VERSION "blueprint-1"

NS_ :

BS_:

BU_: ClimateECU BMS EngineECU BodyECU HeadUnit

CM_ "Signal database for the DriveCore HMI vertical platform lab. Single source of truth for CAN bit definitions.";

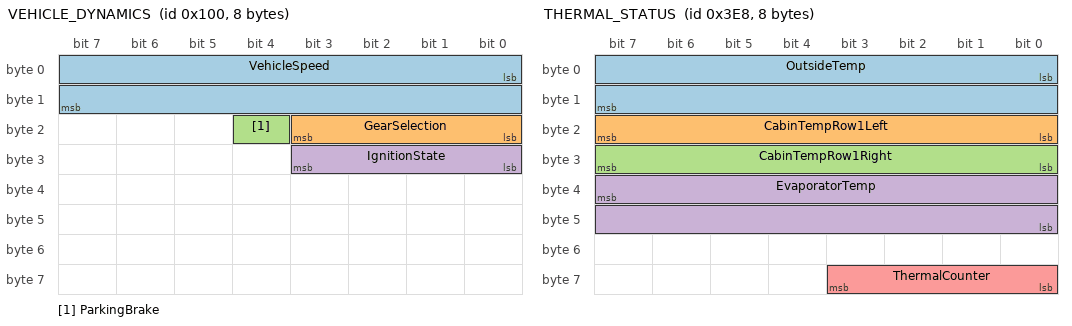
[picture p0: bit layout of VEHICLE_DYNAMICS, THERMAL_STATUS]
BO_ 256 VEHICLE_DYNAMICS: 8 EngineECU
 SG_ VehicleSpeed : 0|16@1+ (0.01,0) [0|250] "km/h" HeadUnit
 SG_ GearSelection : 16|4@1+ (1,0) [0|15] "" HeadUnit
 SG_ ParkingBrake : 20|1@1+ (1,0) [0|1] "" HeadUnit
 SG_ IgnitionState : 24|4@1+ (1,0) [0|15] "" HeadUnit

BO_ 512 BODY_STATUS: 8 BodyECU
 SG_ DoorPos : 0|8@1+ (1,0) [0|255] "" HeadUnit
 SG_ TurnSignal : 8|4@1+ (1,0) [0|15] "" HeadUnit

BO_ 768 HVAC_STATUS: 8 ClimateECU
 SG_ HvacTempSet : 0|8@1+ (0.5,10) [16|30] "degC" HeadUnit

BO_ 1000 THERMAL_STATUS: 8 ClimateECU
 SG_ OutsideTemp : 0|16@1+ (0.1,-40) [-40|125] "degC" HeadUnit
 SG_ CabinTempRow1Left : 16|8@1+ (0.5,-10) [-10|117.5] "degC" HeadUnit
 SG_ CabinTempRow1Right : 24|8@1+ (0.5,-10) [-10|117.5] "degC" HeadUnit
 SG_ EvaporatorTemp : 39|16@0- (0.01,0) [-50|150] "degC" HeadUnit
 SG_ ThermalCounter : 56|4@1+ (1,0) [0|15] "" HeadUnit

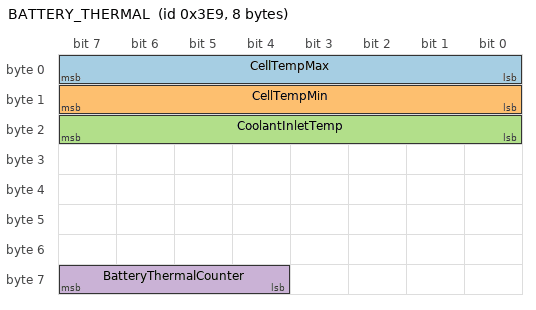
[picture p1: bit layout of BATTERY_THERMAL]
BO_ 1001 BATTERY_THERMAL: 8 BMS
 SG_ CellTempMax : 0|8@1+ (1,-40) [-40|125] "degC" HeadUnit
 SG_ CellTempMin : 8|8@1+ (1,-40) [-40|125] "degC" HeadUnit
 SG_ CoolantInletTemp : 16|8@1+ (1,-40) [-40|125] "degC" HeadUnit
 SG_ BatteryThermalCounter : 60|4@1+ (1,0) [0|15] "" HeadUnit

BA_DEF_ SG_ "VhalProperty" STRING ;
BA_DEF_ SG_ "VhalAreaId" INT 0 2147483647;
BA_DEF_ SG_ "VhalChangeMode" ENUM "ON_CHANGE","CONTINUOUS";
BA_DEF_ SG_ "VhalMinSampleRate" FLOAT 0 1000;
BA_DEF_ SG_ "VhalMaxSampleRate" FLOAT 0 1000;
BA_DEF_DEF_ "VhalProperty" "";
BA_DEF_DEF_ "VhalAreaId" 0;
BA_DEF_DEF_ "VhalChangeMode" "ON_CHANGE";
BA_DEF_DEF_ "VhalMinSampleRate" 1;
BA_DEF_DEF_ "VhalMaxSampleRate" 10;

BA_ "VhalProperty" SG_ 256 VehicleSpeed "PERF_VEHICLE_SPEED";
BA_ "VhalChangeMode" SG_ 256 VehicleSpeed "CONTINUOUS";

BA_ "VhalProperty" SG_ 256 GearSelection "GEAR_SELECTION";
BA_ "VhalProperty" SG_ 256 ParkingBrake "PARKING_BRAKE_ON";
BA_ "VhalProperty" SG_ 256 IgnitionState "IGNITION_STATE";

BA_ "VhalProperty" SG_ 512 DoorPos "DOOR_POS";
BA_ "VhalProperty" SG_ 512 TurnSignal "TURN_SIGNAL_STATE";

BA_ "VhalProperty" SG_ 768 HvacTempSet "HVAC_TEMPERATURE_SET";

BA_ "VhalProperty" SG_ 1000 OutsideTemp "ENV_OUTSIDE_TEMPERATURE";
BA_ "VhalChangeMode" SG_ 1000 OutsideTemp "CONTINUOUS";
BA_ "VhalMaxSampleRate" SG_ 1000 OutsideTemp 2;
BA_ "VhalProperty" SG_ 1000 CabinTempRow1Left "HVAC_TEMPERATURE_CURRENT";
BA_ "VhalAreaId" SG_ 1000 CabinTempRow1Left 49;
BA_ "VhalProperty" SG_ 1000 CabinTempRow1Right "HVAC_TEMPERATURE_CURRENT";
BA_ "VhalAreaId" SG_ 1000 CabinTempRow1Right 68;
BA_ "VhalProperty" SG_ 1001 CellTempMax "VENDOR_BATTERY_CELL_TEMP_MAX";
